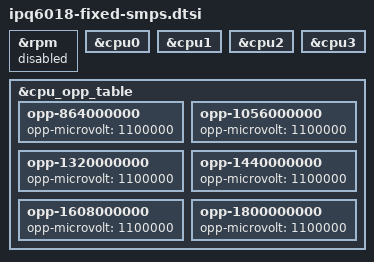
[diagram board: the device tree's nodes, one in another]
// SPDX-License-Identifier: GPL-2.0-only

/*
 * Board does not use companion MP5496 PMIC,
 * but rather uses fixed external SMPS.
 */

&rpm {
	status = "disabled";
};

&cpu0 {
	/delete-property/ cpu-supply;
};

&cpu1 {
	/delete-property/ cpu-supply;
};

&cpu2 {
	/delete-property/ cpu-supply;
};

&cpu3 {
	/delete-property/ cpu-supply;
};

&cpu_opp_table {
	opp-864000000 {
		opp-microvolt = <1100000>;
	};

	opp-1056000000 {
		opp-microvolt = <1100000>;
	};

	opp-1320000000 {
		opp-microvolt = <1100000>;
	};

	opp-1440000000 {
		opp-microvolt = <1100000>;
	};

	opp-1608000000 {
		opp-microvolt = <1100000>;
	};

	opp-1800000000 {
		opp-microvolt = <1100000>;
	};
};
